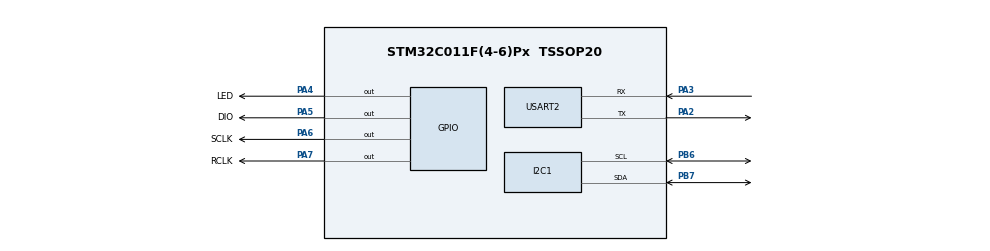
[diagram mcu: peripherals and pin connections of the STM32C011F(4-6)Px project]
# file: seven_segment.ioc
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I2C1.Timing=0x20303E5D
Mcu.Family=STM32C0
Mcu.Name=STM32C011F(4-6)Px
Mcu.Package=TSSOP20
PA13.Mode=Serial_Wire
PA13.Signal=DEBUG_SWDIO
PA14-BOOT0.Mode=Serial_Wire
PA14-BOOT0.Signal=DEBUG_SWCLK
PA2.Mode=Asynchronous
PA2.Signal=USART2_TX
PA3.Mode=Asynchronous
PA3.Signal=USART2_RX
PA4.GPIO_Label=LED
PA4.PinState=GPIO_PIN_SET
PA4.Signal=GPIO_Output
PA5.GPIO_Label=DIO
PA5.Signal=GPIO_Output
PA6.GPIO_Label=SCLK
PA6.Signal=GPIO_Output
PA7.GPIO_Label=RCLK
PA7.Signal=GPIO_Output
PB6.GPIO_Pu=GPIO_PULLUP
PB6.Mode=I2C
PB6.Signal=I2C1_SCL
PB7.GPIO_Pu=GPIO_PULLUP
PB7.Mode=I2C
PB7.Signal=I2C1_SDA
ProjectManager.HeapSize=0x200
ProjectManager.StackSize=0x400
ProjectManager.TargetToolchain=STM32CubeIDE
RCC.ADCFreq_Value=48000000
RCC.AHBFreq_Value=48000000
RCC.CortexFreq_Value=48000000
RCC.EXTERNAL_CLOCK_VALUE=12288000
RCC.HCLKFreq_Value=48000000
RCC.HSE_VALUE=8000000
RCC.HSISYSCLKDivider=RCC_HSI_DIV1
RCC.HSI_VALUE=48000000
RCC.LSE_VALUE=32768
RCC.SYSCLKFreq_VALUE=48000000
USART2.VirtualMode-Asynchronous=VM_ASYNC
board=custom

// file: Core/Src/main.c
/* USER CODE BEGIN Header */
/**
  ******************************************************************************
  * @file           : main.c
  * @brief          : Main program body
  ******************************************************************************
  * @attention
  *
  * Copyright (c) 2024 STMicroelectronics.
  * All rights reserved.
  *
  * This software is licensed under terms that can be found in the LICENSE file
  * in the root directory of this software component.
  * If no LICENSE file comes with this software, it is provided AS-IS.
  *
  ******************************************************************************
  */
/* USER CODE END Header */
#include "main.h"
#include "i2c.h"
#include "usart.h"
#include "gpio.h"

/* USER CODE BEGIN Includes */
#include "segment.h"
/* USER CODE END Includes */

void SystemClock_Config(void);

int main(void)
{

  /* MCU Configuration--------------------------------------------------------*/

  /* Reset of all peripherals, Initializes the Flash interface and the Systick. */
  HAL_Init();

  /* Configure the system clock */
  SystemClock_Config();

  /* Initialize all configured peripherals */
  MX_GPIO_Init();
  MX_I2C1_Init();
  MX_USART2_UART_Init();
  /* USER CODE BEGIN 2 */
  uint16_t cnt = 0;
  uint32_t update_disp_step_time = 0;
  /* USER CODE END 2 */

  /* Infinite loop */
  /* USER CODE BEGIN WHILE */
  while (1)
  {
//  	dispError();
//  	dispDynamic(cnt);
//  	if (HAL_GetTick()-update_disp_step_time >= 200)
//  	{
//  		update_disp_step_time = HAL_GetTick();
//  		disp_step++;
//  		if (disp_step == 9)
//  		{
//  			disp_step = 0;
//  			HAL_Delay(500);
//  			cnt++;
//  		}
//  	}
  	dispStatic(cnt);
  	if (HAL_GetTick()-update_disp_step_time >= 200)
		{
				update_disp_step_time = HAL_GetTick();
				cnt++;
		}

    /* USER CODE END WHILE */

  }
}

void SystemClock_Config(void)
{
  RCC_OscInitTypeDef RCC_OscInitStruct = {0};
  RCC_ClkInitTypeDef RCC_ClkInitStruct = {0};

  /** Initializes the RCC Oscillators according to the specified parameters
  * in the RCC_OscInitTypeDef structure.
  */
  RCC_OscInitStruct.OscillatorType = RCC_OSCILLATORTYPE_HSI;
  RCC_OscInitStruct.HSIState = RCC_HSI_ON;
  RCC_OscInitStruct.HSIDiv = RCC_HSI_DIV1;
  RCC_OscInitStruct.HSICalibrationValue = RCC_HSICALIBRATION_DEFAULT;
  if (HAL_RCC_OscConfig(&RCC_OscInitStruct) != HAL_OK)
  {
    Error_Handler();
  }

  /** Initializes the CPU, AHB and APB buses clocks
  */
  RCC_ClkInitStruct.ClockType = RCC_CLOCKTYPE_HCLK|RCC_CLOCKTYPE_SYSCLK
                              |RCC_CLOCKTYPE_PCLK1;
  RCC_ClkInitStruct.SYSCLKSource = RCC_SYSCLKSOURCE_HSI;
  RCC_ClkInitStruct.SYSCLKDivider = RCC_SYSCLK_DIV1;
  RCC_ClkInitStruct.AHBCLKDivider = RCC_HCLK_DIV1;
  RCC_ClkInitStruct.APB1CLKDivider = RCC_APB1_DIV1;

  if (HAL_RCC_ClockConfig(&RCC_ClkInitStruct, FLASH_LATENCY_1) != HAL_OK)
  {
    Error_Handler();
  }
}

void Error_Handler(void)
{
  __disable_irq();
  while (1)
  {
  }
}
